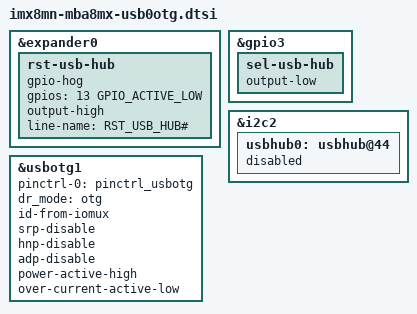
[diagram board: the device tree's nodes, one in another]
// SPDX-License-Identifier: (GPL-2.0-or-later OR MIT)
/*
 * Copyright 2020-2021 TQ-Systems GmbH
 */


&expander0 {
	rst-usb-hub {
		gpio-hog;
		gpios = <13 GPIO_ACTIVE_LOW>;
		output-high;
		line-name = "RST_USB_HUB#";
	};
};

&gpio3 {
	sel-usb-hub {
		output-low;
	};
};

&i2c2 {
	usbhub0: usbhub@44 {
		status = "disabled";
	};	
};

&usbotg1 {
	pinctrl-names = "default";
	pinctrl-0 = <&pinctrl_usbotg>;
	dr_mode = "otg";
	id-from-iomux;
	srp-disable;
	hnp-disable;
	adp-disable;
	power-active-high;
	over-current-active-low;
	status = "okay";
};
